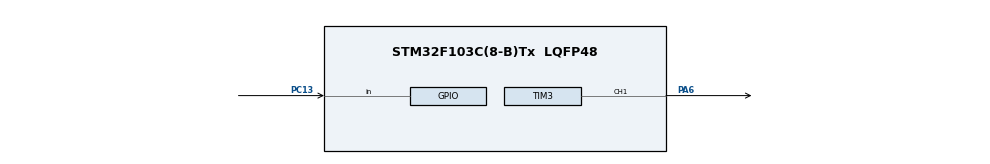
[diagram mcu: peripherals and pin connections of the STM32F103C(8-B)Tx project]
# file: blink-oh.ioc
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Mcu.Family=STM32F1
RCC.APB2Freq_Value=8000000
TIM3.Prescaler=84-1
SH.S_TIM3_CH1.0=TIM3_CH1,PWM Generation1 CH1
PC13-TAMPER-RTC.Signal=GPIO_Input
Mcu.Name=STM32F103C(8-B)Tx
VP_SYS_VS_ND.Mode=No_Debug
Mcu.Package=LQFP48
PA6.Signal=S_TIM3_CH1
ProjectManager.StackSize=0x400
SH.S_TIM2_CH2.0=TIM2_CH2
ProjectManager.HeapSize=0x200
ProjectManager.TargetToolchain=STM32CubeIDE
NVIC.PriorityGroup=NVIC_PRIORITYGROUP_4
TIM3.Period=100-1
RCC.APB1Freq_Value=8000000
PA1.Signal=S_TIM2_CH2
TIM3.Channel-PWM\ Generation1\ CH1=TIM_CHANNEL_1
VP_TIM3_VS_ClockSourceINT.Mode=Internal
board=custom

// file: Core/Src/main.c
/* USER CODE BEGIN Header */
/**
  ******************************************************************************
  * @file           : main.c
  * @brief          : Main program body
  ******************************************************************************
  * @attention
  *
  * <h2><center>&copy; Copyright (c) 2021 STMicroelectronics.
  * All rights reserved.</center></h2>
  *
  * This software component is licensed by ST under BSD 3-Clause license,
  * the "License"; You may not use this file except in compliance with the
  * License. You may obtain a copy of the License at:
  *                        opensource.org/licenses/BSD-3-Clause
  *
  ******************************************************************************
  */
/* USER CODE END Header */
#include "main.h"

TIM_HandleTypeDef htim3;

/* USER CODE BEGIN PV */
	int duty = 0;
/* USER CODE END PV */

void SystemClock_Config(void);
static void MX_GPIO_Init(void);
static void MX_TIM3_Init(void);

int main(void)
{

  /* MCU Configuration--------------------------------------------------------*/

  /* Reset of all peripherals, Initializes the Flash interface and the Systick. */
  HAL_Init();

  /* Configure the system clock */
  SystemClock_Config();

  /* Initialize all configured peripherals */
  MX_GPIO_Init();
  MX_TIM3_Init();

  /* Infinite loop */
  /* USER CODE BEGIN WHILE */
  HAL_TIM_PWM_Start (&htim3, TIM_CHANNEL_1);

  while (1)
  {
	  htim3.Instance->CCR1 = duty ;
	  HAL_Delay (25);
	  duty += 1;
	  if(duty == 100){
	  while (duty > 0){
		  htim3.Instance->CCR1 = duty ;
		  HAL_Delay (25);
		  duty -= 1;
	  }
  }
  }
  /* USER CODE END 3 */
}

void SystemClock_Config(void)
{
  RCC_OscInitTypeDef RCC_OscInitStruct = {0};
  RCC_ClkInitTypeDef RCC_ClkInitStruct = {0};

  /** Initializes the RCC Oscillators according to the specified parameters
  * in the RCC_OscInitTypeDef structure.
  */
  RCC_OscInitStruct.OscillatorType = RCC_OSCILLATORTYPE_HSI;
  RCC_OscInitStruct.HSIState = RCC_HSI_ON;
  RCC_OscInitStruct.HSICalibrationValue = RCC_HSICALIBRATION_DEFAULT;
  RCC_OscInitStruct.PLL.PLLState = RCC_PLL_NONE;
  if (HAL_RCC_OscConfig(&RCC_OscInitStruct) != HAL_OK)
  {
    Error_Handler();
  }
  /** Initializes the CPU, AHB and APB buses clocks
  */
  RCC_ClkInitStruct.ClockType = RCC_CLOCKTYPE_HCLK|RCC_CLOCKTYPE_SYSCLK
                              |RCC_CLOCKTYPE_PCLK1|RCC_CLOCKTYPE_PCLK2;
  RCC_ClkInitStruct.SYSCLKSource = RCC_SYSCLKSOURCE_HSI;
  RCC_ClkInitStruct.AHBCLKDivider = RCC_SYSCLK_DIV1;
  RCC_ClkInitStruct.APB1CLKDivider = RCC_HCLK_DIV1;
  RCC_ClkInitStruct.APB2CLKDivider = RCC_HCLK_DIV1;

  if (HAL_RCC_ClockConfig(&RCC_ClkInitStruct, FLASH_LATENCY_0) != HAL_OK)
  {
    Error_Handler();
  }
}

static void MX_TIM3_Init(void)
{

  TIM_ClockConfigTypeDef sClockSourceConfig = {0};
  TIM_MasterConfigTypeDef sMasterConfig = {0};
  TIM_OC_InitTypeDef sConfigOC = {0};

  htim3.Instance = TIM3;
  htim3.Init.Prescaler = 84-1;
  htim3.Init.CounterMode = TIM_COUNTERMODE_UP;
  htim3.Init.Period = 100-1;
  htim3.Init.ClockDivision = TIM_CLOCKDIVISION_DIV1;
  htim3.Init.AutoReloadPreload = TIM_AUTORELOAD_PRELOAD_DISABLE;
  if (HAL_TIM_Base_Init(&htim3) != HAL_OK)
  {
    Error_Handler();
  }
  sClockSourceConfig.ClockSource = TIM_CLOCKSOURCE_INTERNAL;
  if (HAL_TIM_ConfigClockSource(&htim3, &sClockSourceConfig) != HAL_OK)
  {
    Error_Handler();
  }
  if (HAL_TIM_PWM_Init(&htim3) != HAL_OK)
  {
    Error_Handler();
  }
  sMasterConfig.MasterOutputTrigger = TIM_TRGO_RESET;
  sMasterConfig.MasterSlaveMode = TIM_MASTERSLAVEMODE_DISABLE;
  if (HAL_TIMEx_MasterConfigSynchronization(&htim3, &sMasterConfig) != HAL_OK)
  {
    Error_Handler();
  }
  sConfigOC.OCMode = TIM_OCMODE_PWM1;
  sConfigOC.Pulse = 0;
  sConfigOC.OCPolarity = TIM_OCPOLARITY_HIGH;
  sConfigOC.OCFastMode = TIM_OCFAST_DISABLE;
  if (HAL_TIM_PWM_ConfigChannel(&htim3, &sConfigOC, TIM_CHANNEL_1) != HAL_OK)
  {
    Error_Handler();
  }
  HAL_TIM_MspPostInit(&htim3);

}

static void MX_GPIO_Init(void)
{
  GPIO_InitTypeDef GPIO_InitStruct = {0};

  /* GPIO Ports Clock Enable */
  __HAL_RCC_GPIOC_CLK_ENABLE();
  __HAL_RCC_GPIOA_CLK_ENABLE();

  /*Configure GPIO pin : PC13 */
  GPIO_InitStruct.Pin = GPIO_PIN_13;
  GPIO_InitStruct.Mode = GPIO_MODE_INPUT;
  GPIO_InitStruct.Pull = GPIO_NOPULL;
  HAL_GPIO_Init(GPIOC, &GPIO_InitStruct);

  /*Configure GPIO pin : PA1 */
  GPIO_InitStruct.Pin = GPIO_PIN_1;
  GPIO_InitStruct.Mode = GPIO_MODE_AF_PP;
  GPIO_InitStruct.Speed = GPIO_SPEED_FREQ_LOW;
  HAL_GPIO_Init(GPIOA, &GPIO_InitStruct);

}

void Error_Handler(void)
{
  __disable_irq();
  while (1)
  {
  }
}

/************************ (C) COPYRIGHT STMicroelectronics *****END OF FILE****/
